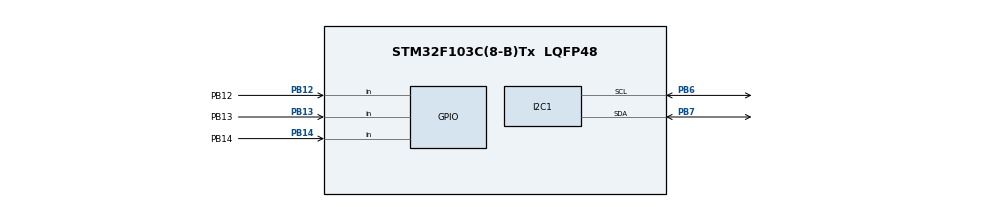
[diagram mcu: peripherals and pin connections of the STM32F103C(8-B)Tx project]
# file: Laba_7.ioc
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Mcu.Family=STM32F1
Mcu.Name=STM32F103C(8-B)Tx
Mcu.Package=LQFP48
NVIC.PriorityGroup=NVIC_PRIORITYGROUP_4
PA13.Mode=Serial_Wire
PA13.Signal=SYS_JTMS-SWDIO
PA14.Mode=Serial_Wire
PA14.Signal=SYS_JTCK-SWCLK
PB12.GPIO_Label=PB12
PB12.GPIO_PuPd=GPIO_PULLUP
PB12.Signal=GPIO_Input
PB13.GPIO_Label=PB13
PB13.GPIO_PuPd=GPIO_PULLUP
PB13.Signal=GPIO_Input
PB14.GPIO_Label=PB14
PB14.GPIO_PuPd=GPIO_PULLUP
PB14.Signal=GPIO_Input
PB6.Mode=I2C
PB6.Signal=I2C1_SCL
PB7.Mode=I2C
PB7.Signal=I2C1_SDA
ProjectManager.HeapSize=0x200
ProjectManager.StackSize=0x400
ProjectManager.TargetToolchain=STM32CubeIDE
RCC.APB1Freq_Value=8000000
RCC.APB2Freq_Value=8000000
board=custom

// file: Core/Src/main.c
/* USER CODE BEGIN Header */
#include "lcd.h"
#include "string.h"
/**
 *
 ******************************************************************************
 * @file           : main.c
 * @brief          : Main program body
 ******************************************************************************
 * @attention
 *
 * Copyright (c) 2025 STMicroelectronics.
 * All rights reserved.
 *
 * This software is licensed under terms that can be found in the LICENSE file
 * in the root directory of this software component.
 * If no LICENSE file comes with this software, it is provided AS-IS.
 *
 ******************************************************************************
 */
/* USER CODE END Header */
#include "main.h"

/* USER CODE BEGIN PD */
#define PCF8574_address 0x24  // подставить адрес конкретного дисплейного
LCD1602 scr;
/* USER CODE END PD */

I2C_HandleTypeDef hi2c1;

void SystemClock_Config(void);
static void MX_GPIO_Init(void);
static void MX_I2C1_Init(void);

int main(void) {
    /* USER CODE BEGIN 1 */
    LCD1602 scr;
    scr.hi2c = &hi2c1;
    scr.DevAddress = (PCF8574_address << 1);

    /* USER CODE END 1 */

    /* MCU
     * Configuration--------------------------------------------------------*/

    /* Reset of all peripherals, Initializes the Flash interface and the
     * Systick. */
    HAL_Init();

    /* Configure the system clock */
    SystemClock_Config();

    /* Initialize all configured peripherals */
    MX_GPIO_Init();
    MX_I2C1_Init();
    /* USER CODE BEGIN 2 */
    initLCD(&scr);

    /* USER CODE END 2 */

    /* Infinite loop */
    /* USER CODE BEGIN WHILE */

    int i = 0;
    while (1) {
        if (HAL_GPIO_ReadPin(GPIOB, GPIO_PIN_12) == GPIO_PIN_SET) {
            writeStringLCD(&scr, "Z");
        }
        if (HAL_GPIO_ReadPin(GPIOB, GPIO_PIN_13) == GPIO_PIN_SET) {
            writeStringLCD(&scr, "O");
        }
        if (HAL_GPIO_ReadPin(GPIOB, GPIO_PIN_14) == GPIO_PIN_SET) {
            writeStringLCD(&scr, "V");
        }
    }

    /* USER CODE END 3 */
}

void SystemClock_Config(void) {
    RCC_OscInitTypeDef RCC_OscInitStruct = {0};
    RCC_ClkInitTypeDef RCC_ClkInitStruct = {0};

    /** Initializes the RCC Oscillators according to the specified parameters
     * in the RCC_OscInitTypeDef structure.
     */
    RCC_OscInitStruct.OscillatorType = RCC_OSCILLATORTYPE_HSI;
    RCC_OscInitStruct.HSIState = RCC_HSI_ON;
    RCC_OscInitStruct.HSICalibrationValue = RCC_HSICALIBRATION_DEFAULT;
    RCC_OscInitStruct.PLL.PLLState = RCC_PLL_NONE;
    if (HAL_RCC_OscConfig(&RCC_OscInitStruct) != HAL_OK) {
        Error_Handler();
    }

    /** Initializes the CPU, AHB and APB buses clocks
     */
    RCC_ClkInitStruct.ClockType = RCC_CLOCKTYPE_HCLK | RCC_CLOCKTYPE_SYSCLK |
                                  RCC_CLOCKTYPE_PCLK1 | RCC_CLOCKTYPE_PCLK2;
    RCC_ClkInitStruct.SYSCLKSource = RCC_SYSCLKSOURCE_HSI;
    RCC_ClkInitStruct.AHBCLKDivider = RCC_SYSCLK_DIV1;
    RCC_ClkInitStruct.APB1CLKDivider = RCC_HCLK_DIV1;
    RCC_ClkInitStruct.APB2CLKDivider = RCC_HCLK_DIV1;

    if (HAL_RCC_ClockConfig(&RCC_ClkInitStruct, FLASH_LATENCY_0) != HAL_OK) {
        Error_Handler();
    }
}

static void MX_I2C1_Init(void) {

    hi2c1.Instance = I2C1;
    hi2c1.Init.ClockSpeed = 100000;
    hi2c1.Init.DutyCycle = I2C_DUTYCYCLE_2;
    hi2c1.Init.OwnAddress1 = 0;
    hi2c1.Init.AddressingMode = I2C_ADDRESSINGMODE_7BIT;
    hi2c1.Init.DualAddressMode = I2C_DUALADDRESS_DISABLE;
    hi2c1.Init.OwnAddress2 = 0;
    hi2c1.Init.GeneralCallMode = I2C_GENERALCALL_DISABLE;
    hi2c1.Init.NoStretchMode = I2C_NOSTRETCH_DISABLE;
    if (HAL_I2C_Init(&hi2c1) != HAL_OK) {
        Error_Handler();
    }
}

static void MX_GPIO_Init(void) {

    /* GPIO Ports Clock Enable */
    __HAL_RCC_GPIOA_CLK_ENABLE();
    __HAL_RCC_GPIOB_CLK_ENABLE();

}

/* USER CODE BEGIN 4 */

void HAL_GPIO_EXTI_Callback(uint16_t GPIO_Pin) {
    //	if (GPIO_Pin == GPIO_PIN_12) //check if external button triggered
    //	{
    //		writeStringLCD(&scr, "Z");
    //	}
    //	else if (GPIO_Pin == GPIO_PIN_13)
    //	{
    //		writeStringLCD(&scr, "O");
    //	}
    //	else if (GPIO_Pin == GPIO_PIN_14)
    //	{
    //		writeStringLCD(&scr, "V");
    //	}
}

/* USER CODE END 4 */

void Error_Handler(void) {
    /* USER CODE BEGIN Error_Handler_Debug */
    /* User can add his own implementation to report the HAL error return state
     */
    __disable_irq();
    while (1) {
    }
    /* USER CODE END Error_Handler_Debug */
}

#ifdef USE_FULL_ASSERT
/**
 * @brief  Reports the name of the source file and the source line number
 *         where the assert_param error has occurred.
 * @param  file: pointer to the source file name
 * @param  line: assert_param error line source number
 * @retval None
 */
void assert_failed(uint8_t *file, uint32_t line) {
    /* USER CODE BEGIN 6 */
    /* User can add his own implementation to report the file name and line
       number, ex: printf("Wrong parameters value: file %s on line %d\r\n",
       file, line) */
    /* USER CODE END 6 */
}
#endif /* USE_FULL_ASSERT */
